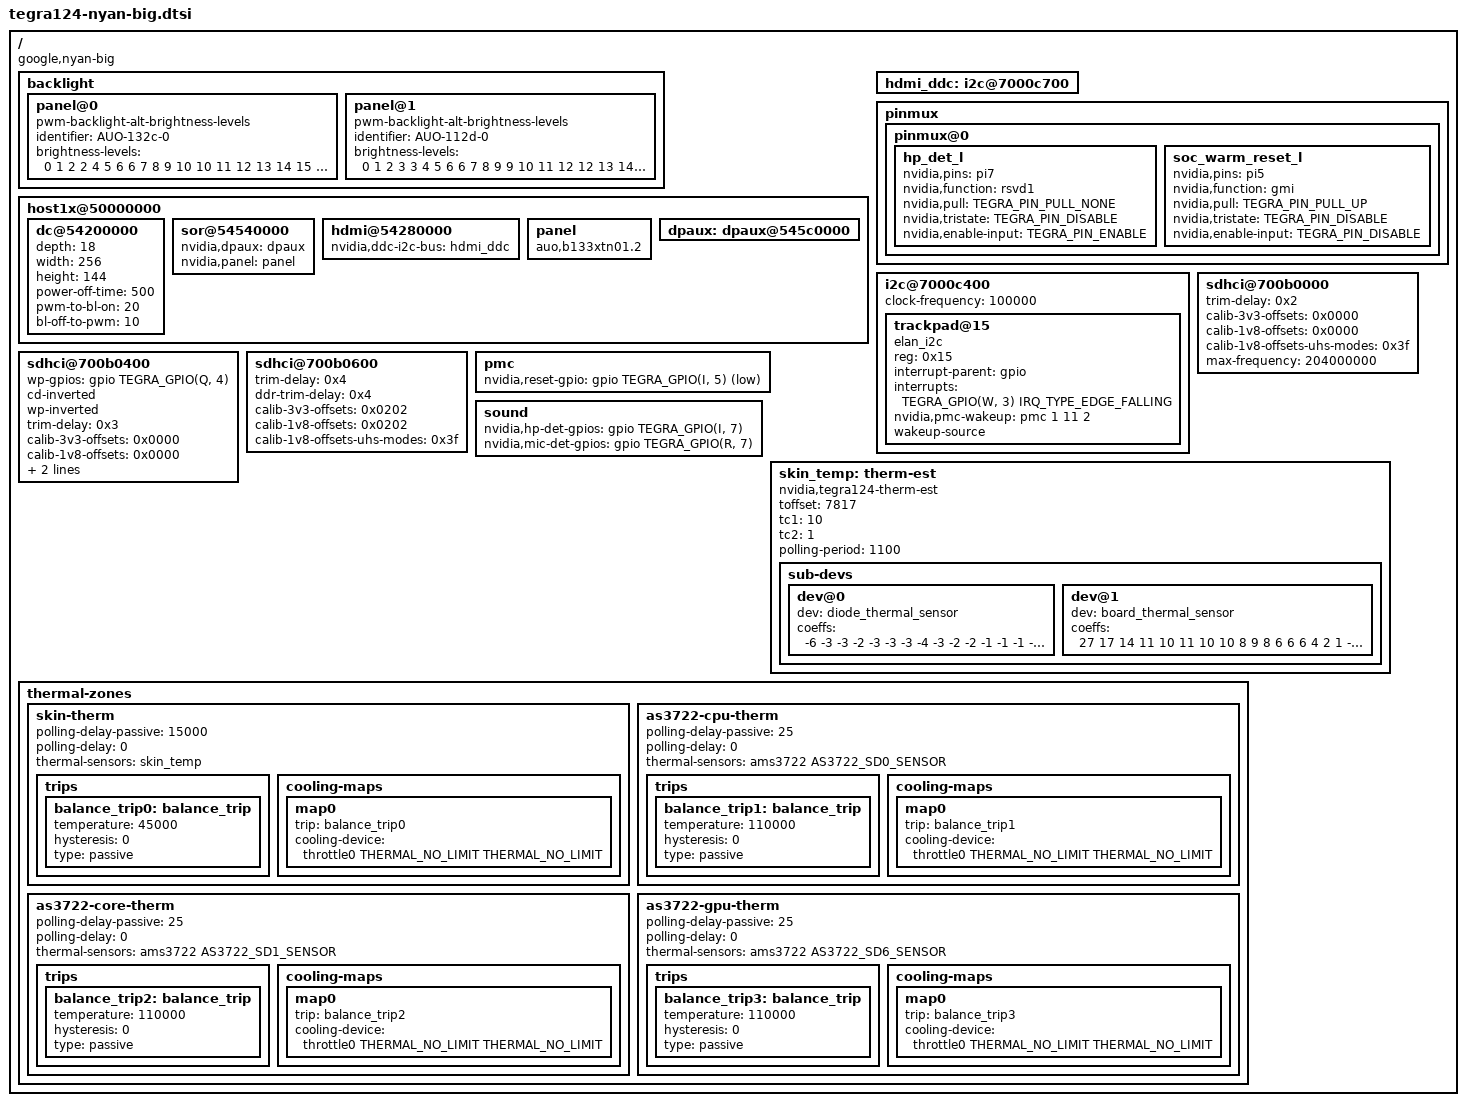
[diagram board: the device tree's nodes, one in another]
#include "tegra124-nyan.dtsi"
#include "tegra124-nyan-big-emc.dtsi"

/ {
	compatible = "google,nyan-big", "google,nyan", "nvidia,tegra124";

	backlight {
		panel@0 {
			compatible = "pwm-backlight-alt-brightness-levels";
			identifier = "AUO-132c-0";
			brightness-levels =
				<  0   1   2   2   4   5   6   6
				   7   8   9  10  10  11  12  13
				  14  15  15  16  17  18  19  20
				  20  21  22  23  24  25  25  26
				  27  28  29  30  30  31  32  33
				  34  35  35  36  37  38  39  40
				  40  41  42  43  44  45  45  46
				  47  48  49  50  50  51  52  53
				  54  55  55  56  57  58  59  60
				  60  61  62  63  64  65  65  66
				  67  68  69  70  70  71  72  73
				  74  75  76  77  77  78  79  80
				  81  82  82  83  84  85  86  87
				  88  89  90  91  92  93  95  95
				  96  98  98 100 101 102 103 104
				 105 106 107 108 110 111 112 113
				 114 115 116 117 118 119 121 121
				 123 124 125 126 127 128 129 130
				 132 133 134 135 136 137 138 139
				 141 141 143 144 145 146 147 148
				 149 150 151 152 154 155 156 157
				 158 159 160 161 162 164 165 166
				 167 168 169 170 171 172 173 175
				 176 177 178 179 180 182 183 183
				 184 186 187 188 189 190 192 193
				 193 194 195 197 198 199 200 201
				 202 204 204 206 207 208 209 210
				 211 212 213 214 216 217 218 219
				 220 222 223 224 225 226 227 228
				 230 230 232 233 234 235 236 237
				 238 239 241 242 243 244 245 246
				 247 249 250 251 252 253 254 255
				 256>;
		};

		panel@1 {
			compatible = "pwm-backlight-alt-brightness-levels";
			identifier = "AUO-112d-0";
			brightness-levels =
				<  0   1   2   3   3   4   5   6
				   6   7   8   9   9  10  11  12
				  12  13  14  14  15  16  17  17
				  18  19  19  20  21  22  23  23
				  24  25  25  26  27  28  28  29
				  30  31  31  32  33  34  34  35
				  36  37  37  38  39  39  40  41
				  42  42  43  44  45  46  46  47
				  48  48  49  50  51  51  52  53
				  54  54  55  56  56  57  58  59
				  59  60  61  61  62  63  64  64
				  65  66  67  68  68  69  70  71
				  71  72  73  74  74  75  76  77
				  78  79  80  81  82  83  84  85
				  86  87  89  90  90  92  93  94
				  95  96  98  98 100 101 101 103
				 104 105 106 107 108 109 110 111
				 113 114 115 116 117 118 119 121
				 122 123 124 125 126 127 128 129
				 130 131 133 134 135 136 137 138
				 140 141 142 143 144 146 147 148
				 149 150 151 152 154 155 156 157
				 158 159 161 162 163 164 165 167
				 168 169 170 171 172 173 175 176
				 177 178 180 181 182 183 185 185
				 187 188 189 190 191 192 194 195
				 197 197 199 200 201 202 204 205
				 206 207 208 210 211 213 213 215
				 216 217 218 220 221 222 223 225
				 226 227 228 229 230 231 233 234
				 235 237 238 239 240 242 243 244
				 245 246 248 249 250 251 253 254
				 256>;
		};
	};

	host1x@50000000 {
		dc@54200000 {
			depth = <18>;
			width = <256>;
			height = <144>;
			power-off-time = <500>;
			pwm-to-bl-on = <20>;
			bl-off-to-pwm = <10>;
		};

		sor@54540000 {
			status = "okay";

			nvidia,dpaux = <&dpaux>;
			nvidia,panel = <&panel>;
		};

		hdmi@54280000 {
			nvidia,ddc-i2c-bus = <&hdmi_ddc>;
		};

		panel: panel {
			compatible = "auo,b133xtn01.2", "simple-panel";
		};

		dpaux: dpaux@545c0000 {
			status = "okay";
		};
	};

	hdmi_ddc: i2c@7000c700 {
		status = "okay";
	};

	pinmux {
		pinmux@0 {
			hp_det_l {
				nvidia,pins = "pi7";
				nvidia,function = "rsvd1";
				nvidia,pull = <TEGRA_PIN_PULL_NONE>;
				nvidia,tristate = <TEGRA_PIN_DISABLE>;
				nvidia,enable-input = <TEGRA_PIN_ENABLE>;
			};
			soc_warm_reset_l {
				nvidia,pins = "pi5";
				nvidia,function = "gmi";
				nvidia,pull = <TEGRA_PIN_PULL_UP>;
				nvidia,tristate = <TEGRA_PIN_DISABLE>;
				nvidia,enable-input = <TEGRA_PIN_DISABLE>;
			};
		};
	};

	i2c@7000c400 {
		clock-frequency = <100000>;

		trackpad@15 {
			compatible = "elan_i2c";
			reg = <0x15>;
			interrupt-parent = <&gpio>;
			interrupts = <TEGRA_GPIO(W, 3) IRQ_TYPE_EDGE_FALLING>;
			nvidia,pmc-wakeup = <&pmc 1 11 2>;
			wakeup-source;
		};
	};

	sdhci@700b0000 {
		trim-delay = <0x2>;
		calib-3v3-offsets = <0x0000>;
		calib-1v8-offsets = <0x0000>;
		calib-1v8-offsets-uhs-modes = <0x3f>;
		max-frequency = <204000000>;
	};

	sdhci@700b0400 {
		wp-gpios = <&gpio TEGRA_GPIO(Q, 4) GPIO_ACTIVE_HIGH>;
		cd-inverted;
		wp-inverted;
		trim-delay = <0x3>;
		calib-3v3-offsets = <0x0000>;
		calib-1v8-offsets = <0x0000>;
		calib-1v8-offsets-uhs-modes = <0x3f>;
		max-frequency = <204000000>;
	};

	sdhci@700b0600 {
		trim-delay = <0x4>;
		ddr-trim-delay = <0x4>;
		calib-3v3-offsets = <0x0202>;
		calib-1v8-offsets = <0x0202>;
		calib-1v8-offsets-uhs-modes = <0x3f>;
	};

	pmc {
		nvidia,reset-gpio = <&gpio TEGRA_GPIO(I, 5) GPIO_ACTIVE_LOW>;
	};

	sound {
		nvidia,hp-det-gpios = <&gpio TEGRA_GPIO(I, 7) GPIO_ACTIVE_HIGH>;
		nvidia,mic-det-gpios = <&gpio TEGRA_GPIO(R, 7)
							GPIO_ACTIVE_HIGH>;
	};

	skin_temp: therm-est {
		compatible = "nvidia,tegra124-therm-est";
		toffset = <7817>;
		tc1 = <10>;
		tc2 = <1>;
		polling-period = <1100>;

		#thermal-sensor-cells = <0>;

		sub-devs {
			dev@0 {
				dev = <&diode_thermal_sensor>;
				coeffs = "-6 -3 -3 -2 -3 -3 -3 -4 -3 -2 -2 -1 -1 -1 -1 -1 -1 -2 -2 -5";
			};

			dev@1 {
				dev = <&board_thermal_sensor>;
				coeffs = "27 17 14 11 10 11 10 10 8 9 8 6 6 6 4 2 1 -3 -5 -13";
			};
		};
	};

	thermal-zones {
		skin-therm {
			polling-delay-passive = <15000>; /* milliseconds */
			polling-delay = <0>; /* milliseconds */

			thermal-sensors = <&skin_temp>;

			trips {
				balance_trip0: balance_trip {
					temperature = <45000>; /* millicelsius */
					hysteresis = <0>; /* millicelsius */
					type = "passive";
				};
			};

			cooling-maps {
				map0 {
					trip = <&balance_trip0>;
					cooling-device = <&throttle0 THERMAL_NO_LIMIT THERMAL_NO_LIMIT>;
				};
			};
		};
		as3722-cpu-therm {
			polling-delay-passive = <25>; /* milliseconds */
			polling-delay = <0>; /* milliseconds */
			thermal-sensors = <&ams3722 AS3722_SD0_SENSOR>;

			trips {
				balance_trip1: balance_trip {
					temperature = <110000>; /* millicelsius */
					hysteresis = <0>; /* millicelsius */
					type = "passive";
				};
			};

			cooling-maps {
				map0 {
					trip = <&balance_trip1>;
					cooling-device = <&throttle0 THERMAL_NO_LIMIT THERMAL_NO_LIMIT>;
				};
			};
		};
		as3722-core-therm {
			polling-delay-passive = <25>; /* milliseconds */
			polling-delay = <0>; /* milliseconds */
			thermal-sensors = <&ams3722 AS3722_SD1_SENSOR>;

			trips {
				balance_trip2: balance_trip {
					temperature = <110000>; /* millicelsius */
					hysteresis = <0>; /* millicelsius */
					type = "passive";
				};
			};

			cooling-maps {
				map0 {
					trip = <&balance_trip2>;
					cooling-device = <&throttle0 THERMAL_NO_LIMIT THERMAL_NO_LIMIT>;
				};
			};
		};
		as3722-gpu-therm {
			polling-delay-passive = <25>; /* milliseconds */
			polling-delay = <0>; /* milliseconds */
			thermal-sensors = <&ams3722 AS3722_SD6_SENSOR>;

			trips {
				balance_trip3: balance_trip {
					temperature = <110000>; /* millicelsius */
					hysteresis = <0>; /* millicelsius */
					type = "passive";
				};
			};

			cooling-maps {
				map0 {
					trip = <&balance_trip3>;
					cooling-device = <&throttle0 THERMAL_NO_LIMIT THERMAL_NO_LIMIT>;
				};
			};
		};
	};
};
